# BAT32G133B register map
Vendor: CMS; Series: BAT32G133B; File version: 1.2
CPU: CM0+ r0p1, little endian, no MPU, no FPU, VTOR, 2 interrupt priority bits
Registers are 8-bit, read-write, reset 0x0 unless marked. A register's access mark holds for its fields unless they carry their own. Offsets are from the block's base; [hi:lo] are bit positions; 'fields as' and 'values as' point back to an identical list.

## RTC — Real-Time clock
Base 0x40044F00
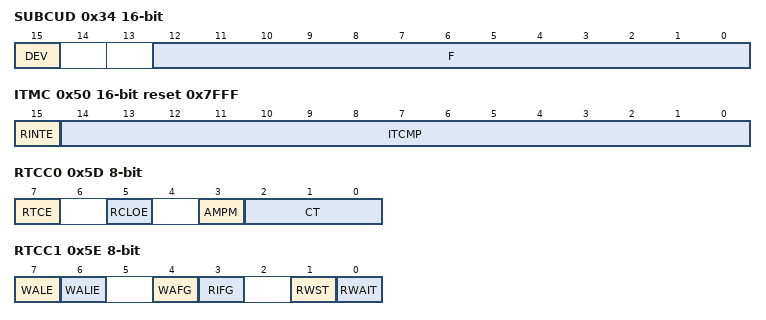
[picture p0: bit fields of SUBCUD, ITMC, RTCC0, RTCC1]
0x34 SUBCUD 16-bit — Watch error correction register
  [15] DEV — watch error correction timing
  [12:0] F — watch error correction value
0x50 ITMC 16-bit reset 0x7FFF — 15-bit interval timer control register
  [15] RINTE — 15-bit interval timer operation control
  [14:0] ITCMP — 15-bit interval timer compare value
0x52 SEC (reset mask 0x7F) — Second count register
0x53 MIN (reset mask 0x7F) — Minute count register
0x54 HOUR reset 0x12 (reset mask 0x3F) — Hour count register
0x55 WEEK (reset mask 0x7) — Week count register
0x56 DAY reset 0x1 (reset mask 0x3F) — Day count register
0x57 MONTH reset 0x1 (reset mask 0x1F) — Month count register
0x58 YEAR — Year count register
0x5A ALARMWM (reset mask 0x7F) — Alarm minute register
0x5B ALARMWH reset 0x12 (reset mask 0x3F) — Alarm hour register
0x5C ALARMWW (reset mask 0x3F) — Alarm week register
0x5D RTCC0 — Real-time clock control register 0
  [7] RTCE — Real-time clock operation control
  [5] RCLOE — RTC1HZ pin output enable
  [3] AMPM — Selection of 12-/24-hour system
  [2:0] CT — Constant-period interrupt (INTRTC) selection
0x5E RTCC1 — Real-time clock control register 1
  [7] WALE — Alarm operation control
  [6] WALIE — Control of alarm interrupt (INTRTC) function operation
  [4] WAFG — Alarm detection status flag
  [3] RIFG — Constant-period interrupt status flag
  [1] RWST — Wait status flag of real-time clock
  [0] RWAIT — Wait control of real-time clock

## PCBZ — Clock/Buzzer output controller
Base 0x40040FA0
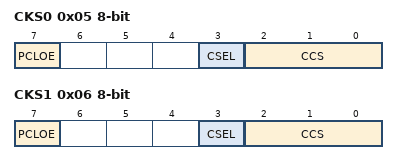
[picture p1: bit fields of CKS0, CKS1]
0x05 CKS0 — Clock output select registers 0
  [7] PCLOE — PCLBUZn pin output enable
  [3] CSEL — PCLBUZn output clock select
  [2:0] CCS — PCLBUZn output clock select
0x06 CKS1 — Clock output select registers 1
  fields as CKS0

## WDT — Watchdog Timer with window
Base 0x40021000
0x01 WDTE (reset mask 0xAC) — Watchdog timer enable register

## ADC — A/D Converter
Base 0x40045000
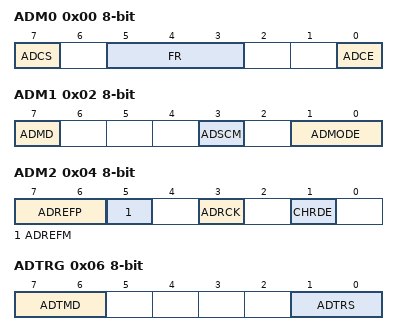
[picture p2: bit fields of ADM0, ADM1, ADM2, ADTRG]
0x00 ADM0 — A/D mode register 0
  [7] ADCS — A/D conversion operation control
  [5:3] FR — A/D conversion clock (fAD) select
  [0] ADCE — A/D enable
0x02 ADM1 — A/D mode register 1
  [7] ADMD — A/D conversion channel select mode
    0=Select mode; 1=Scan mode
  [3] ADSCM — A/D conversion mode
    0=Sequential conversion mode; 1=One-shot conversion mode
  [1:0] ADMODE — A/D mode select
0x04 ADM2 — A/D mode register 2
  [7:6] ADREFP — Selection of the + side reference voltage of A/D converter
    0=VDD (Supplied from VDD); 1=AVREFP0 (Supplied from AVREFP); 2=AVREFP1 (Supplied from inside AVREF of A/D)
  [5] ADREFM — Selection of the - side reference voltage of A/D converter
    0=VSS (Supplied from VSS); 1=AVREFM (Supplied from AVREFM)
  [3] ADRCK — the upper limit and lower limit conversion result values
  [1] CHRDE — output CH number in A/D conversion result in Scan mode
0x06 ADTRG (reset mask 0x33) — A/D mode register 2
  [7:6] ADTMD — A/D conversion trigger mode
  [1:0] ADTRS — A/D hard trigger select
0x08 ADS (reset mask 0xBF) — Analog input channel specification register
0x0A ADLL — Conversion result comparison lower limit setting register
0x0B ADUL reset 0xFF — Conversion result comparison upper limit setting register
0x0C ADNSMP — A/D sampling time control register
0x0E ADCR 16-bit (reset mask 0xFFF) — 12-bit A/D conversion result register
0x0F ADCRH (alternate view of ADCR) — Higher 8-bit A/D conversion result register
0x10 ADTES (reset mask 0x7) — A/D test register
0x11 ADNDIS — A/D charge/discharge control register
0x15 ADSMPWAIT — A/D sampling wait control register
0x16 ADFLG (reset mask 0x1F) — A/D flag register
